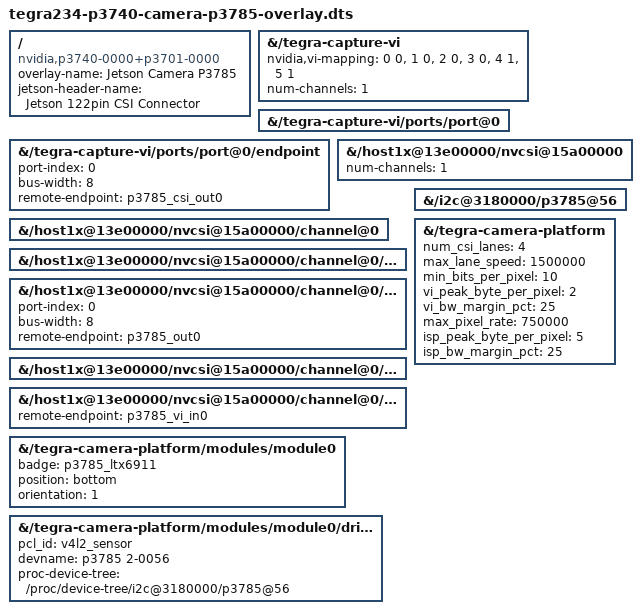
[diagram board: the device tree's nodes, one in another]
/*
 * Copyright (c) 2023, NVIDIA CORPORATION.  All rights reserved.
 *
 * This program is free software; you can redistribute it and/or modify it
 * under the terms and conditions of the GNU General Public License,
 * version 2, as published by the Free Software Foundation.
 *
 * This program is distributed in the hope it will be useful, but WITHOUT
 * ANY WARRANTY; without even the implied warranty of MERCHANTABILITY or
 * FITNESS FOR A PARTICULAR PURPOSE.  See the GNU General Public License for
 * more details.
 *
 * You should have received a copy of the GNU General Public License
 * along with this program.  If not, see <http://www.gnu.org/licenses/>.
 */

/*
 * Device-tree overlay for P3785.
 */


/dts-v1/;
/plugin/;

/ {
	overlay-name = "Jetson Camera P3785 ";
	jetson-header-name = "Jetson 122pin CSI Connector";
	compatible = "nvidia,p3740-0000+p3701-0000", "nvidia,p3740-0002-b01+p3701-0002";

	/* VI number of channels */
	fragment@0 {
		target-path = "/tegra-capture-vi";
		board_config {
			sw-modules = "kernel";
		};
		__overlay__ {
			nvidia,vi-mapping =
				<0 0>,
				<1 0>,
				<2 0>,
				<3 0>,
				<4 1>,
				<5 1>;
			num-channels=<1>;
		};
        };
	fragment@1 {
		target-path = "/tegra-capture-vi/ports/port@0";
		board_config {
			sw-modules = "kernel";
		};
		__overlay__ {
			status = "okay";
		};
	};

	fragment@2 {
		target-path = "/tegra-capture-vi/ports/port@0/endpoint";
		board_config {
			sw-modules = "kernel";
		};
		__overlay__ {
			status = "okay";
			port-index = <0>;
			bus-width = <8>;
			remote-endpoint = <&p3785_csi_out0>;
		};
	};
	fragment@3 {
		target-path = "/host1x@13e00000/nvcsi@15a00000";
		board_config {
			sw-modules = "kernel";
		};
		__overlay__ {
			num-channels = <1>;
		};
	};

	fragment@4 {
		target-path = "/host1x@13e00000/nvcsi@15a00000/channel@0";
		board_config {
			sw-modules = "kernel";
		};
		__overlay__ {
			status = "okay";
		};
	};

	fragment@5 {
		target-path = "/host1x@13e00000/nvcsi@15a00000/channel@0/ports/port@0";
		board_config {
			sw-modules = "kernel";
		};
		__overlay__ {
			status = "okay";
		};
	};

	fragment@6 {
		target-path = "/host1x@13e00000/nvcsi@15a00000/channel@0/ports/port@0/endpoint@0";
		board_config {
			sw-modules = "kernel";
		};
		__overlay__ {
			status = "okay";
			port-index = <0>;
			bus-width = <8>;
			remote-endpoint = <&p3785_out0>;
		};
	};
	fragment@7 {
		target-path = "/host1x@13e00000/nvcsi@15a00000/channel@0/ports/port@1";
		board_config {
			sw-modules = "kernel";
		};
		__overlay__ {
			status = "okay";
		};
	};

	fragment@8 {
		target-path = "/host1x@13e00000/nvcsi@15a00000/channel@0/ports/port@1/endpoint@1";
		board_config {
			sw-modules = "kernel";
		};
		__overlay__ {
			status = "okay";
			remote-endpoint = <&p3785_vi_in0>;
		};
	};

	fragment@9 {
		target-path = "/i2c@3180000/p3785@56";
		board_config {
			sw-modules = "kernel";
		};
		__overlay__ {
			status = "okay";
		};
	};
	fragment@10 {
		target-path = "/tegra-camera-platform";
		board_config {
			sw-modules = "kernel";
		};
		__overlay__ {
			num_csi_lanes = <4>;
			max_lane_speed = <1500000>;
			min_bits_per_pixel = <10>;
			vi_peak_byte_per_pixel = <2>;
			vi_bw_margin_pct = <25>;
			max_pixel_rate = <750000>;
			isp_peak_byte_per_pixel = <5>;
			isp_bw_margin_pct = <25>;
		};
	};
	fragment@11 {
		target-path = "/tegra-camera-platform/modules/module0";
		board_config {
			sw-modules = "kernel";
		};
		__overlay__ {
			status = "okay";
			badge = "p3785_ltx6911";
			position = "bottom";
			orientation = "1";
		};
	};
	fragment@12 {
		target-path = "/tegra-camera-platform/modules/module0/drivernode0";
		board_config {
			sw-modules = "kernel";
		};
		__overlay__ {
			status = "okay";
			pcl_id = "v4l2_sensor";
			devname = "p3785 2-0056";
			proc-device-tree = "/proc/device-tree/i2c@3180000/p3785@56";
		};
	};
};
